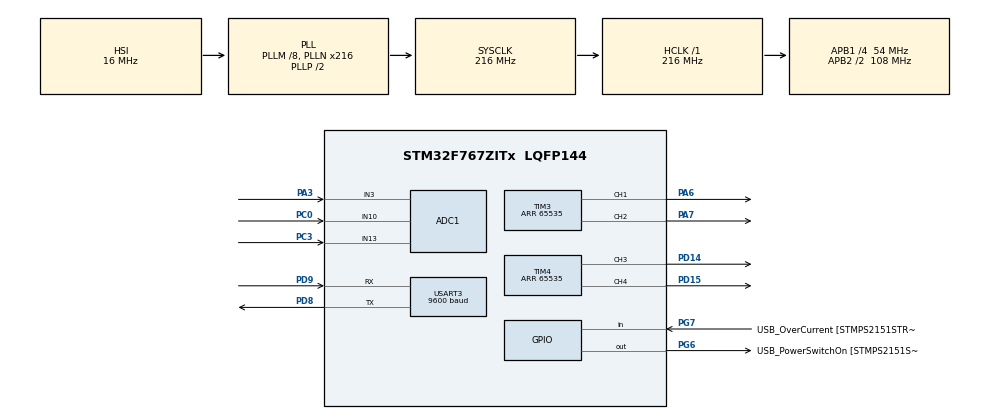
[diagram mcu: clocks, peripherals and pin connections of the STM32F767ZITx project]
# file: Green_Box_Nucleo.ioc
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ADC1.Channel-0\#ChannelRegularConversion=ADC_CHANNEL_3
ADC1.NbrOfConversionFlag=1
ADC1.Rank-0\#ChannelRegularConversion=1
ADC1.SamplingTime-0\#ChannelRegularConversion=ADC_SAMPLETIME_3CYCLES
ADC1.master=1
Mcu.Family=STM32F7
Mcu.Name=STM32F767ZITx
Mcu.Package=LQFP144
NVIC.PriorityGroup=NVIC_PRIORITYGROUP_4
NVIC.USART3_IRQn=true\:0\:0\:false\:false\:true\:true
PA3.Signal=ADCx_IN3
PA6.Signal=S_TIM3_CH1
PA7.Signal=S_TIM3_CH2
PC0.Signal=ADCx_IN10
PC3.Signal=ADCx_IN13
PD14.Signal=S_TIM4_CH3
PD15.GPIO_ModeDefaultPP=GPIO_MODE_AF_PP
PD15.GPIO_PuPd=GPIO_NOPULL
PD15.GPIO_Speed=GPIO_SPEED_FREQ_LOW
PD15.Signal=S_TIM4_CH4
PD8.Mode=Asynchronous
PD8.Signal=USART3_TX
PD9.Mode=Asynchronous
PD9.Signal=USART3_RX
PG6.GPIO_Label=USB_PowerSwitchOn [STMPS2151STR_EN]
PG6.Signal=GPIO_Output
PG7.GPIO_Label=USB_OverCurrent [STMPS2151STR_FAULT]
PG7.Signal=GPIO_Input
ProjectManager.HeapSize=0x200
ProjectManager.StackSize=0x400
ProjectManager.TargetToolchain=MDK-ARM V5
RCC.48MHZClocksFreq_Value=24000000
RCC.AHBFreq_Value=216000000
RCC.APB1CLKDivider=RCC_HCLK_DIV4
RCC.APB1Freq_Value=54000000
RCC.APB1TimFreq_Value=108000000
RCC.APB2CLKDivider=RCC_HCLK_DIV2
RCC.APB2Freq_Value=108000000
RCC.APB2TimFreq_Value=216000000
RCC.CortexFreq_Value=216000000
RCC.HCLKFreq_Value=216000000
RCC.HSE_VALUE=16000000
RCC.HSI_VALUE=16000000
RCC.LSE_VALUE=32768
RCC.PLLM=8
RCC.PLLMUL=RCC_PLL_MUL9
RCC.PLLN=216
RCC.PRESCALERUSB=RCC_USBCLKSOURCE_PLL_DIV1_5
RCC.SYSCLKFreq_VALUE=216000000
RCC.SYSCLKSource=RCC_SYSCLKSOURCE_PLLCLK
RCC.SYSCLKSourceVirtual=RCC_SYSCLKSOURCE_PLLCLK
RCC.USBFreq_Value=216000000
RCC.VCOOutputFreq_Value=432000000
SH.ADCx_IN10.0=ADC1_IN10,IN10
SH.ADCx_IN13.0=ADC1_IN13,IN13
SH.ADCx_IN3.0=ADC1_IN3,IN3
SH.S_TIM3_CH1.0=TIM3_CH1,PWM Generation1 CH1
SH.S_TIM3_CH2.0=TIM3_CH2,PWM Generation2 CH2
SH.S_TIM4_CH3.0=TIM4_CH3,PWM Generation3 CH3
SH.S_TIM4_CH4.0=TIM4_CH4,PWM Generation4 CH4
TIM3.Channel-PWM\ Generation1\ CH1=TIM_CHANNEL_1
TIM3.Channel-PWM\ Generation2\ CH2=TIM_CHANNEL_2
TIM3.Period=65535
TIM4.Channel-PWM\ Generation3\ CH3=TIM_CHANNEL_3
TIM4.Channel-PWM\ Generation4\ CH4=TIM_CHANNEL_4
TIM4.OCFastMode_PWM-PWM\ Generation4\ CH4=TIM_OCFAST_DISABLE
TIM4.OCMode_PWM-PWM\ Generation4\ CH4=TIM_OCMODE_PWM1
TIM4.Period=65535
USART3.BaudRate=9600
USART3.VirtualMode-Asynchronous=VM_ASYNC
USART3.WordLength=WORDLENGTH_8B
VP_TIM3_VS_ClockSourceINT.Mode=Internal
VP_TIM4_VS_ClockSourceINT.Mode=Internal
board=NUCLEO-F767ZI

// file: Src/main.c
/**
  ******************************************************************************
  * File Name          : main.c
  * Description        : Main program body
  ******************************************************************************
  ** This notice applies to any and all portions of this file
  * that are not between comment pairs USER CODE BEGIN and
  * USER CODE END. Other portions of this file, whether
  * inserted by the user or by software development tools
  * are owned by their respective copyright owners.
  *
  * COPYRIGHT(c) 2019 STMicroelectronics
  *
  * Redistribution and use in source and binary forms, with or without modification,
  * are permitted provided that the following conditions are met:
  *   1. Redistributions of source code must retain the above copyright notice,
  *      this list of conditions and the following disclaimer.
  *   2. Redistributions in binary form must reproduce the above copyright notice,
  *      this list of conditions and the following disclaimer in the documentation
  *      and/or other materials provided with the distribution.
  *   3. Neither the name of STMicroelectronics nor the names of its contributors
  *      may be used to endorse or promote products derived from this software
  *      without specific prior written permission.
  *
  * THIS SOFTWARE IS PROVIDED BY THE COPYRIGHT HOLDERS AND CONTRIBUTORS "AS IS"
  * AND ANY EXPRESS OR IMPLIED WARRANTIES, INCLUDING, BUT NOT LIMITED TO, THE
  * IMPLIED WARRANTIES OF MERCHANTABILITY AND FITNESS FOR A PARTICULAR PURPOSE ARE
  * DISCLAIMED. IN NO EVENT SHALL THE COPYRIGHT HOLDER OR CONTRIBUTORS BE LIABLE
  * FOR ANY DIRECT, INDIRECT, INCIDENTAL, SPECIAL, EXEMPLARY, OR CONSEQUENTIAL
  * DAMAGES (INCLUDING, BUT NOT LIMITED TO, PROCUREMENT OF SUBSTITUTE GOODS OR
  * SERVICES; LOSS OF USE, DATA, OR PROFITS; OR BUSINESS INTERRUPTION) HOWEVER
  * CAUSED AND ON ANY THEORY OF LIABILITY, WHETHER IN CONTRACT, STRICT LIABILITY,
  * OR TORT (INCLUDING NEGLIGENCE OR OTHERWISE) ARISING IN ANY WAY OUT OF THE USE
  * OF THIS SOFTWARE, EVEN IF ADVISED OF THE POSSIBILITY OF SUCH DAMAGE.
  *
  ******************************************************************************
  */

#include "main.h"
#include "stm32f7xx_hal.h"

/* USER CODE BEGIN Includes */
#include "main_injection.h"
/* USER CODE END Includes */

ADC_HandleTypeDef hadc1;

TIM_HandleTypeDef htim3;
TIM_HandleTypeDef htim4;

UART_HandleTypeDef huart3;

/* USER CODE BEGIN PV */
/* Private variables ---------------------------------------------------------*/

/* USER CODE END PV */

void SystemClock_Config(void);
static void MX_GPIO_Init(void);
static void MX_USART3_UART_Init(void);
static void MX_TIM4_Init(void);
static void MX_TIM3_Init(void);
static void MX_ADC1_Init(void);

void HAL_TIM_MspPostInit(TIM_HandleTypeDef *htim);

/* USER CODE BEGIN PFP */
/* Private function prototypes -----------------------------------------------*/

/* USER CODE END PFP */

int main(void)
{

  /* MCU Configuration----------------------------------------------------------*/

  /* Reset of all peripherals, Initializes the Flash interface and the Systick. */
  HAL_Init();

  /* Configure the system clock */
  SystemClock_Config();

  /* Initialize all configured peripherals */
  MX_GPIO_Init();
  MX_USART3_UART_Init();
  MX_TIM4_Init();
  MX_TIM3_Init();
  MX_ADC1_Init();

  /* USER CODE BEGIN 2 */
	Init_Peripheral();
  /* USER CODE END 2 */

  /* Infinite loop */
  while (1)
  {

  /* USER CODE BEGIN 3 */
	Loop();
  }
  /* USER CODE END 3 */

}

/** System Clock Configuration
*/
void SystemClock_Config(void)
{

  RCC_OscInitTypeDef RCC_OscInitStruct;
  RCC_ClkInitTypeDef RCC_ClkInitStruct;
  RCC_PeriphCLKInitTypeDef PeriphClkInitStruct;

    /**Configure the main internal regulator output voltage
    */
  __HAL_RCC_PWR_CLK_ENABLE();

  __HAL_PWR_VOLTAGESCALING_CONFIG(PWR_REGULATOR_VOLTAGE_SCALE1);

    /**Initializes the CPU, AHB and APB busses clocks
    */
  RCC_OscInitStruct.OscillatorType = RCC_OSCILLATORTYPE_HSI;
  RCC_OscInitStruct.HSIState = RCC_HSI_ON;
  RCC_OscInitStruct.HSICalibrationValue = 16;
  RCC_OscInitStruct.PLL.PLLState = RCC_PLL_ON;
  RCC_OscInitStruct.PLL.PLLSource = RCC_PLLSOURCE_HSI;
  RCC_OscInitStruct.PLL.PLLM = 8;
  RCC_OscInitStruct.PLL.PLLN = 216;
  RCC_OscInitStruct.PLL.PLLP = RCC_PLLP_DIV2;
  RCC_OscInitStruct.PLL.PLLQ = 2;
  if (HAL_RCC_OscConfig(&RCC_OscInitStruct) != HAL_OK)
  {
    _Error_Handler(__FILE__, __LINE__);
  }

    /**Activate the Over-Drive mode
    */
  if (HAL_PWREx_EnableOverDrive() != HAL_OK)
  {
    _Error_Handler(__FILE__, __LINE__);
  }

    /**Initializes the CPU, AHB and APB busses clocks
    */
  RCC_ClkInitStruct.ClockType = RCC_CLOCKTYPE_HCLK|RCC_CLOCKTYPE_SYSCLK
                              |RCC_CLOCKTYPE_PCLK1|RCC_CLOCKTYPE_PCLK2;
  RCC_ClkInitStruct.SYSCLKSource = RCC_SYSCLKSOURCE_PLLCLK;
  RCC_ClkInitStruct.AHBCLKDivider = RCC_SYSCLK_DIV1;
  RCC_ClkInitStruct.APB1CLKDivider = RCC_HCLK_DIV4;
  RCC_ClkInitStruct.APB2CLKDivider = RCC_HCLK_DIV2;

  if (HAL_RCC_ClockConfig(&RCC_ClkInitStruct, FLASH_LATENCY_7) != HAL_OK)
  {
    _Error_Handler(__FILE__, __LINE__);
  }

  PeriphClkInitStruct.PeriphClockSelection = RCC_PERIPHCLK_USART3;
  PeriphClkInitStruct.Usart3ClockSelection = RCC_USART3CLKSOURCE_PCLK1;
  if (HAL_RCCEx_PeriphCLKConfig(&PeriphClkInitStruct) != HAL_OK)
  {
    _Error_Handler(__FILE__, __LINE__);
  }

    /**Configure the Systick interrupt time
    */
  HAL_SYSTICK_Config(HAL_RCC_GetHCLKFreq()/1000);

    /**Configure the Systick
    */
  HAL_SYSTICK_CLKSourceConfig(SYSTICK_CLKSOURCE_HCLK);

  /* SysTick_IRQn interrupt configuration */
  HAL_NVIC_SetPriority(SysTick_IRQn, 0, 0);
}

/* ADC1 init function */
static void MX_ADC1_Init(void)
{

  ADC_ChannelConfTypeDef sConfig;

    /**Configure the global features of the ADC (Clock, Resolution, Data Alignment and number of conversion)
    */
  hadc1.Instance = ADC1;
  hadc1.Init.ClockPrescaler = ADC_CLOCK_SYNC_PCLK_DIV4;
  hadc1.Init.Resolution = ADC_RESOLUTION_12B;
  hadc1.Init.ScanConvMode = DISABLE;
  hadc1.Init.ContinuousConvMode = DISABLE;
  hadc1.Init.DiscontinuousConvMode = DISABLE;
  hadc1.Init.ExternalTrigConvEdge = ADC_EXTERNALTRIGCONVEDGE_NONE;
  hadc1.Init.ExternalTrigConv = ADC_SOFTWARE_START;
  hadc1.Init.DataAlign = ADC_DATAALIGN_RIGHT;
  hadc1.Init.NbrOfConversion = 1;
  hadc1.Init.DMAContinuousRequests = DISABLE;
  hadc1.Init.EOCSelection = ADC_EOC_SINGLE_CONV;
  if (HAL_ADC_Init(&hadc1) != HAL_OK)
  {
    _Error_Handler(__FILE__, __LINE__);
  }

    /**Configure for the selected ADC regular channel its corresponding rank in the sequencer and its sample time.
    */
  sConfig.Channel = ADC_CHANNEL_3;
  sConfig.Rank = 1;
  sConfig.SamplingTime = ADC_SAMPLETIME_3CYCLES;
  if (HAL_ADC_ConfigChannel(&hadc1, &sConfig) != HAL_OK)
  {
    _Error_Handler(__FILE__, __LINE__);
  }

}

/* TIM3 init function */
static void MX_TIM3_Init(void)
{

  TIM_ClockConfigTypeDef sClockSourceConfig;
  TIM_MasterConfigTypeDef sMasterConfig;
  TIM_OC_InitTypeDef sConfigOC;

  htim3.Instance = TIM3;
  htim3.Init.Prescaler = 0;
  htim3.Init.CounterMode = TIM_COUNTERMODE_UP;
  htim3.Init.Period = 65535;
  htim3.Init.ClockDivision = TIM_CLOCKDIVISION_DIV1;
  htim3.Init.AutoReloadPreload = TIM_AUTORELOAD_PRELOAD_DISABLE;
  if (HAL_TIM_Base_Init(&htim3) != HAL_OK)
  {
    _Error_Handler(__FILE__, __LINE__);
  }

  sClockSourceConfig.ClockSource = TIM_CLOCKSOURCE_INTERNAL;
  if (HAL_TIM_ConfigClockSource(&htim3, &sClockSourceConfig) != HAL_OK)
  {
    _Error_Handler(__FILE__, __LINE__);
  }

  if (HAL_TIM_PWM_Init(&htim3) != HAL_OK)
  {
    _Error_Handler(__FILE__, __LINE__);
  }

  sMasterConfig.MasterOutputTrigger = TIM_TRGO_RESET;
  sMasterConfig.MasterSlaveMode = TIM_MASTERSLAVEMODE_DISABLE;
  if (HAL_TIMEx_MasterConfigSynchronization(&htim3, &sMasterConfig) != HAL_OK)
  {
    _Error_Handler(__FILE__, __LINE__);
  }

  sConfigOC.OCMode = TIM_OCMODE_PWM1;
  sConfigOC.Pulse = 0;
  sConfigOC.OCPolarity = TIM_OCPOLARITY_HIGH;
  sConfigOC.OCFastMode = TIM_OCFAST_DISABLE;
  if (HAL_TIM_PWM_ConfigChannel(&htim3, &sConfigOC, TIM_CHANNEL_1) != HAL_OK)
  {
    _Error_Handler(__FILE__, __LINE__);
  }

  if (HAL_TIM_PWM_ConfigChannel(&htim3, &sConfigOC, TIM_CHANNEL_2) != HAL_OK)
  {
    _Error_Handler(__FILE__, __LINE__);
  }

  HAL_TIM_MspPostInit(&htim3);

}

/* TIM4 init function */
static void MX_TIM4_Init(void)
{

  TIM_ClockConfigTypeDef sClockSourceConfig;
  TIM_MasterConfigTypeDef sMasterConfig;
  TIM_OC_InitTypeDef sConfigOC;

  htim4.Instance = TIM4;
  htim4.Init.Prescaler = 0;
  htim4.Init.CounterMode = TIM_COUNTERMODE_UP;
  htim4.Init.Period = 65535;
  htim4.Init.ClockDivision = TIM_CLOCKDIVISION_DIV1;
  htim4.Init.AutoReloadPreload = TIM_AUTORELOAD_PRELOAD_DISABLE;
  if (HAL_TIM_Base_Init(&htim4) != HAL_OK)
  {
    _Error_Handler(__FILE__, __LINE__);
  }

  sClockSourceConfig.ClockSource = TIM_CLOCKSOURCE_INTERNAL;
  if (HAL_TIM_ConfigClockSource(&htim4, &sClockSourceConfig) != HAL_OK)
  {
    _Error_Handler(__FILE__, __LINE__);
  }

  if (HAL_TIM_PWM_Init(&htim4) != HAL_OK)
  {
    _Error_Handler(__FILE__, __LINE__);
  }

  sMasterConfig.MasterOutputTrigger = TIM_TRGO_RESET;
  sMasterConfig.MasterSlaveMode = TIM_MASTERSLAVEMODE_DISABLE;
  if (HAL_TIMEx_MasterConfigSynchronization(&htim4, &sMasterConfig) != HAL_OK)
  {
    _Error_Handler(__FILE__, __LINE__);
  }

  sConfigOC.OCMode = TIM_OCMODE_PWM1;
  sConfigOC.Pulse = 0;
  sConfigOC.OCPolarity = TIM_OCPOLARITY_HIGH;
  sConfigOC.OCFastMode = TIM_OCFAST_DISABLE;
  if (HAL_TIM_PWM_ConfigChannel(&htim4, &sConfigOC, TIM_CHANNEL_3) != HAL_OK)
  {
    _Error_Handler(__FILE__, __LINE__);
  }

  if (HAL_TIM_PWM_ConfigChannel(&htim4, &sConfigOC, TIM_CHANNEL_4) != HAL_OK)
  {
    _Error_Handler(__FILE__, __LINE__);
  }

  HAL_TIM_MspPostInit(&htim4);

}

/* USART3 init function */
static void MX_USART3_UART_Init(void)
{

  huart3.Instance = USART3;
  huart3.Init.BaudRate = 9600;
  huart3.Init.WordLength = UART_WORDLENGTH_8B;
  huart3.Init.StopBits = UART_STOPBITS_1;
  huart3.Init.Parity = UART_PARITY_NONE;
  huart3.Init.Mode = UART_MODE_TX_RX;
  huart3.Init.HwFlowCtl = UART_HWCONTROL_NONE;
  huart3.Init.OverSampling = UART_OVERSAMPLING_16;
  huart3.Init.OneBitSampling = UART_ONE_BIT_SAMPLE_DISABLE;
  huart3.AdvancedInit.AdvFeatureInit = UART_ADVFEATURE_NO_INIT;
  if (HAL_UART_Init(&huart3) != HAL_OK)
  {
    _Error_Handler(__FILE__, __LINE__);
  }

}

/** Configure pins as
        * Analog
        * Input
        * Output
        * EVENT_OUT
        * EXTI
*/
static void MX_GPIO_Init(void)
{

  GPIO_InitTypeDef GPIO_InitStruct;

  /* GPIO Ports Clock Enable */
  __HAL_RCC_GPIOC_CLK_ENABLE();
  __HAL_RCC_GPIOA_CLK_ENABLE();
  __HAL_RCC_GPIOD_CLK_ENABLE();
  __HAL_RCC_GPIOG_CLK_ENABLE();

  /*Configure GPIO pin Output Level */
  HAL_GPIO_WritePin(USB_PowerSwitchOn_GPIO_Port, USB_PowerSwitchOn_Pin, GPIO_PIN_RESET);

  /*Configure GPIO pin : USB_PowerSwitchOn_Pin */
  GPIO_InitStruct.Pin = USB_PowerSwitchOn_Pin;
  GPIO_InitStruct.Mode = GPIO_MODE_OUTPUT_PP;
  GPIO_InitStruct.Pull = GPIO_NOPULL;
  GPIO_InitStruct.Speed = GPIO_SPEED_FREQ_LOW;
  HAL_GPIO_Init(USB_PowerSwitchOn_GPIO_Port, &GPIO_InitStruct);

  /*Configure GPIO pin : USB_OverCurrent_Pin */
  GPIO_InitStruct.Pin = USB_OverCurrent_Pin;
  GPIO_InitStruct.Mode = GPIO_MODE_INPUT;
  GPIO_InitStruct.Pull = GPIO_NOPULL;
  HAL_GPIO_Init(USB_OverCurrent_GPIO_Port, &GPIO_InitStruct);

}

void _Error_Handler(char * file, int line)
{
  while(1)
  {
  }
}

/************************ (C) COPYRIGHT STMicroelectronics *****END OF FILE****/
